AUTOSAR XML (schema 00048)
standard types defined: Boolean, UInt16, UInt32, UInt8, boolean, uint16, uint32, uint8
package /AppNvM_SRPrm_pkg/AppNvM_SRPrm_dt
  impl type rt_Array_UInt8_4: category=ARRAY
    element rt_Array_UInt8_4: array-size=4, array-size-semantics=FIXED-SIZE, implementation-data-type=UInt8
package /AppNvM_SRPrm_pkg/AppNvM_SRPrm_if
  102 x sender receiver interface:
    gCFG_bLCK_PowerFillerCapCfg: invalidation-policy{data-element=gCFG_bLCK_PowerFillerCapCfg/Val, handle-invalid=DONT-INVALIDATE}
      data Val: sw-calibration-access=READ-ONLY, type=AppNvM_SRPrm_dt/Boolean
    gCFG_bReCabinTSnsrAvl: invalidation-policy{data-element=gCFG_bReCabinTSnsrAvl/Val, handle-invalid=DONT-INVALIDATE}
      data Val: type=AppNvM_SRPrm_dt/Boolean
    gCFG_bRLDoorFramelessGlassCfg: invalidation-policy{data-element=gCFG_bRLDoorFramelessGlassCfg/Val, handle-invalid=DONT-INVALIDATE}
      data Val: sw-calibration-access=READ-ONLY, type=AppNvM_SRPrm_dt/Boolean
    gCFG_bRRDoorFramelessGlassCfg: invalidation-policy{data-element=gCFG_bRRDoorFramelessGlassCfg/Val, handle-invalid=DONT-INVALIDATE}
      data Val: sw-calibration-access=READ-ONLY, type=AppNvM_SRPrm_dt/Boolean
    gCFG_bWndVentilationFunCfg: invalidation-policy{data-element=gCFG_bWndVentilationFunCfg/Val, handle-invalid=DONT-INVALIDATE}
      data Val: sw-calibration-access=READ-ONLY, type=AppNvM_SRPrm_dt/Boolean
    gCFG_RearWiperPresent: invalidation-policy{data-element=gCFG_RearWiperPresent/Val, handle-invalid=DONT-INVALIDATE}
      data Val: sw-calibration-access=READ-ONLY, type=AppNvM_SRPrm_dt/Boolean
    gCFG_u8LocalSideWinSwType: invalidation-policy{data-element=gCFG_u8LocalSideWinSwType/Val, handle-invalid=DONT-INVALIDATE}
      data Val: type=UInt8
    gCFG_u8ReBlowrCtrlFreqTyp: invalidation-policy{data-element=gCFG_u8ReBlowrCtrlFreqTyp/Val, handle-invalid=DONT-INVALIDATE}
      data Val: type=UInt8
    gCFG_u8ReBlowrCtrlTyp: invalidation-policy{data-element=gCFG_u8ReBlowrCtrlTyp/Val, handle-invalid=DONT-INVALIDATE}
      data Val: type=UInt8
    gCFG_u8ReHVACBoxTyp: invalidation-policy{data-element=gCFG_u8ReHVACBoxTyp/Val, handle-invalid=DONT-INVALIDATE}
      data Val: type=UInt8
    gCFG_u8SsmInFunctionConfig: invalidation-policy{data-element=gCFG_u8SsmInFunctionConfig/Val, handle-invalid=DONT-INVALIDATE}
      data Val: type=UInt8
    gCFG_u8SsmInVariantCoding: invalidation-policy{data-element=gCFG_u8SsmInVariantCoding/Val, handle-invalid=DONT-INVALIDATE}
      data Val: type=rt_Array_UInt8_4
    gCFG_u8WndAPCfgSet: invalidation-policy{data-element=gCFG_u8WndAPCfgSet/Val, handle-invalid=DONT-INVALIDATE}
      data Val: sw-calibration-access=READ-ONLY, type=UInt8
    gCFG_u8WndVentilationPst: invalidation-policy{data-element=gCFG_u8WndVentilationPst/Val, handle-invalid=DONT-INVALIDATE}
      data Val: sw-calibration-access=READ-ONLY, type=UInt8
    gPRM_bChargeLightEnableCfg: invalidation-policy{data-element=gPRM_bChargeLightEnableCfg/Val, handle-invalid=DONT-INVALIDATE}
      data Val: sw-calibration-access=READ-ONLY, type=AppNvM_SRPrm_dt/Boolean
    gPRM_bCHMSLEnableCfg: invalidation-policy{data-element=gPRM_bCHMSLEnableCfg/Val, handle-invalid=DONT-INVALIDATE}
      data Val: sw-calibration-access=READ-ONLY, type=AppNvM_SRPrm_dt/Boolean
    gPRM_bParkLightEnableCfg: invalidation-policy{data-element=gPRM_bParkLightEnableCfg/Val, handle-invalid=DONT-INVALIDATE}
      data Val: sw-calibration-access=READ-ONLY, type=AppNvM_SRPrm_dt/Boolean
    gPRM_bPODCinchFunEnCfgRL: invalidation-policy{data-element=gPRM_bPODCinchFunEnCfgRL/Val, handle-invalid=DONT-INVALIDATE}
      data Val: sw-calibration-access=READ-ONLY, type=AppNvM_SRPrm_dt/Boolean
    gPRM_bPODCinchFunEnCfgRR: invalidation-policy{data-element=gPRM_bPODCinchFunEnCfgRR/Val, handle-invalid=DONT-INVALIDATE}
      data Val: sw-calibration-access=READ-ONLY, type=AppNvM_SRPrm_dt/Boolean
    gPRM_bPODRelsCinchFunEnCfgRL: invalidation-policy{data-element=gPRM_bPODRelsCinchFunEnCfgRL/Val, handle-invalid=DONT-INVALIDATE}
      data Val: type=DcmAppl_DID_dt/Boolean
    gPRM_bPODRelsCinchFunEnCfgRR: invalidation-policy{data-element=gPRM_bPODRelsCinchFunEnCfgRR/Val, handle-invalid=DONT-INVALIDATE}
      data Val: type=DcmAppl_DID_dt/Boolean
    gPRM_bPositionLightEnableCfg: invalidation-policy{data-element=gPRM_bPositionLightEnableCfg/Val, handle-invalid=DONT-INVALIDATE}
      data Val: sw-calibration-access=READ-ONLY, type=AppNvM_SRPrm_dt/Boolean
    gPRM_bPositionLightTimingOFFEnableCfg: invalidation-policy{data-element=gPRM_bPositionLightTimingOFFEnableCfg/Val, handle-invalid=DONT-INVALIDATE}
      data Val: sw-calibration-access=READ-ONLY, type=AppNvM_SRPrm_dt/Boolean
    gPRM_bRearFogLightEnableCfg: invalidation-policy{data-element=gPRM_bRearFogLightEnableCfg/Val, handle-invalid=DONT-INVALIDATE}
      data Val: sw-calibration-access=READ-ONLY, type=AppNvM_SRPrm_dt/Boolean
    gPRM_bRearTurnLightType: invalidation-policy{data-element=gPRM_bRearTurnLightType/Val, handle-invalid=DONT-INVALIDATE}
      data Val: type=DcmAppl_DID_dt/Boolean
    gPRM_bRearTurnONRearPositionOFFCfg: invalidation-policy{data-element=gPRM_bRearTurnONRearPositionOFFCfg/Val, handle-invalid=DONT-INVALIDATE}
      data Val: sw-calibration-access=READ-ONLY, type=AppNvM_SRPrm_dt/Boolean
    gPRM_bReverseLightEnableCfg: invalidation-policy{data-element=gPRM_bReverseLightEnableCfg/Val, handle-invalid=DONT-INVALIDATE}
      data Val: sw-calibration-access=READ-ONLY, type=AppNvM_SRPrm_dt/Boolean
    gPRM_bSideBrkLightEnableCfg: invalidation-policy{data-element=gPRM_bSideBrkLightEnableCfg/Val, handle-invalid=DONT-INVALIDATE}
      data Val: sw-calibration-access=READ-ONLY, type=AppNvM_SRPrm_dt/Boolean
    gPRM_bTDCSStopEnableCfg: invalidation-policy{data-element=gPRM_bTDCSStopEnableCfg/Val, handle-invalid=DONT-INVALIDATE}
      data Val: sw-calibration-access=READ-ONLY, type=AppNvM_SRPrm_dt/Boolean
    gPRM_bTurnLightEnableCfg: invalidation-policy{data-element=gPRM_bTurnLightEnableCfg/Val, handle-invalid=DONT-INVALIDATE}
      data Val: sw-calibration-access=READ-ONLY, type=AppNvM_SRPrm_dt/Boolean
    gPRM_u16HallHighLevel: invalidation-policy{data-element=gPRM_u16HallHighLevel/Val, handle-invalid=DONT-INVALIDATE}
      data Val: sw-calibration-access=READ-ONLY, type=UInt16
    gPRM_u16HallLowLevel: invalidation-policy{data-element=gPRM_u16HallLowLevel/Val, handle-invalid=DONT-INVALIDATE}
      data Val: sw-calibration-access=READ-ONLY, type=UInt16
    gPRM_u16OverVoltImmPrm: invalidation-policy{data-element=gPRM_u16OverVoltImmPrm/Val, handle-invalid=DONT-INVALIDATE}
      data Val: sw-calibration-access=READ-ONLY, type=UInt16
    gPRM_u16OverVoltPrm: invalidation-policy{data-element=gPRM_u16OverVoltPrm/Val, handle-invalid=DONT-INVALIDATE}
      data Val: sw-calibration-access=READ-ONLY, type=UInt16
    gPRM_u16OverVoltRecoverPrm: invalidation-policy{data-element=gPRM_u16OverVoltRecoverPrm/Val, handle-invalid=DONT-INVALIDATE}
      data Val: sw-calibration-access=READ-ONLY, type=UInt16
    gPRM_u16UnderVoltImmPrm: invalidation-policy{data-element=gPRM_u16UnderVoltImmPrm/Val, handle-invalid=DONT-INVALIDATE}
      data Val: sw-calibration-access=READ-ONLY, type=UInt16
    gPRM_u16UnderVoltPrm: invalidation-policy{data-element=gPRM_u16UnderVoltPrm/Val, handle-invalid=DONT-INVALIDATE}
      data Val: sw-calibration-access=READ-ONLY, type=UInt16
    gPRM_u16UnderVoltRecoverPrm: invalidation-policy{data-element=gPRM_u16UnderVoltRecoverPrm/Val, handle-invalid=DONT-INVALIDATE}
      data Val: sw-calibration-access=READ-ONLY, type=UInt16
    gPRM_u32TempCoolDownPrm: invalidation-policy{data-element=gPRM_u32TempCoolDownPrm/Val, handle-invalid=DONT-INVALIDATE}
      data Val: sw-calibration-access=READ-ONLY, type=UInt32
    gPRM_u32TempDisableAllPrm: invalidation-policy{data-element=gPRM_u32TempDisableAllPrm/Val, handle-invalid=DONT-INVALIDATE}
      data Val: sw-calibration-access=READ-ONLY, type=UInt32
    gPRM_u32TempDisableUpPrm: invalidation-policy{data-element=gPRM_u32TempDisableUpPrm/Val, handle-invalid=DONT-INVALIDATE}
      data Val: sw-calibration-access=READ-ONLY, type=UInt32
    gPRM_u8EnaThermalProtPrm: invalidation-policy{data-element=gPRM_u8EnaThermalProtPrm/Val, handle-invalid=DONT-INVALIDATE}
      data Val: sw-calibration-access=READ-ONLY, type=UInt8
    gPRM_u8FLEnableAutoUpPrm: invalidation-policy{data-element=gPRM_u8FLEnableAutoUpPrm/Val, handle-invalid=DONT-INVALIDATE}
      data Val: sw-calibration-access=READ-ONLY, type=UInt8
    gPRM_u8FREnableAutoUpPrm: invalidation-policy{data-element=gPRM_u8FREnableAutoUpPrm/Val, handle-invalid=DONT-INVALIDATE}
      data Val: sw-calibration-access=READ-ONLY, type=UInt8
    gPRM_u8HallFilterTime: invalidation-policy{data-element=gPRM_u8HallFilterTime/Val, handle-invalid=DONT-INVALIDATE}
      data Val: sw-calibration-access=READ-ONLY, type=UInt8
    gPRM_u8HallOverTime: invalidation-policy{data-element=gPRM_u8HallOverTime/Val, handle-invalid=DONT-INVALIDATE}
      data Val: sw-calibration-access=READ-ONLY, type=UInt8
    gPRM_u8IniHoldTimer: invalidation-policy{data-element=gPRM_u8IniHoldTimer/Val, handle-invalid=DONT-INVALIDATE}
      data Val: sw-calibration-access=READ-ONLY, type=UInt8
    gPRM_u8LicencePlateLightShutDown: invalidation-policy{data-element=gPRM_u8LicencePlateLightShutDown/Val, handle-invalid=DONT-INVALIDATE}
      data Val: sw-calibration-access=READ-ONLY, type=UInt8
    gPRM_u8LocalKeepWakeUpCfg: invalidation-policy{data-element=gPRM_u8LocalKeepWakeUpCfg/Val, handle-invalid=DONT-INVALIDATE}
      data Val: sw-calibration-access=READ-ONLY, type=UInt8
    gPRM_u8MaxRuntimePrm: invalidation-policy{data-element=gPRM_u8MaxRuntimePrm/Val, handle-invalid=DONT-INVALIDATE}
      data Val: sw-calibration-access=READ-ONLY, type=UInt8
    gPRM_u8MinReverseTimePrm: invalidation-policy{data-element=gPRM_u8MinReverseTimePrm/Val, handle-invalid=DONT-INVALIDATE}
      data Val: sw-calibration-access=READ-ONLY, type=UInt8
    gPRM_u8PODCinchActiCntForOverheat: invalidation-policy{data-element=gPRM_u8PODCinchActiCntForOverheat/Val, handle-invalid=DONT-INVALIDATE}
      data Val: sw-calibration-access=READ-ONLY, type=UInt8
    gPRM_u8PODCinchInhibitForOverheat: invalidation-policy{data-element=gPRM_u8PODCinchInhibitForOverheat/Val, handle-invalid=DONT-INVALIDATE}
      data Val: sw-calibration-access=READ-ONLY, type=UInt8
    gPRM_u8PODCinchTWForOverheat: invalidation-policy{data-element=gPRM_u8PODCinchTWForOverheat/Val, handle-invalid=DONT-INVALIDATE}
      data Val: sw-calibration-access=READ-ONLY, type=UInt8
    gPRM_u8PODPowerRelesActiCntForOverheat: invalidation-policy{data-element=gPRM_u8PODPowerRelesActiCntForOverheat/Val, handle-invalid=DONT-INVALIDATE}
      data Val: sw-calibration-access=READ-ONLY, type=UInt8
    gPRM_u8PODPowerRelesInhibitForOverheat: invalidation-policy{data-element=gPRM_u8PODPowerRelesInhibitForOverheat/Val, handle-invalid=DONT-INVALIDATE}
      data Val: sw-calibration-access=READ-ONLY, type=UInt8
    gPRM_u8PODPowerRelesTWForOverheat: invalidation-policy{data-element=gPRM_u8PODPowerRelesTWForOverheat/Val, handle-invalid=DONT-INVALIDATE}
      data Val: sw-calibration-access=READ-ONLY, type=UInt8
    gPRM_u8PODTCinchActv: invalidation-policy{data-element=gPRM_u8PODTCinchActv/Val, handle-invalid=DONT-INVALIDATE}
      data Val: sw-calibration-access=READ-ONLY, type=UInt8
    gPRM_u8PODTmrCinchOper: invalidation-policy{data-element=gPRM_u8PODTmrCinchOper/Val, handle-invalid=DONT-INVALIDATE}
      data Val: sw-calibration-access=READ-ONLY, type=UInt8
    gPRM_u8PODTmrCinchRst: invalidation-policy{data-element=gPRM_u8PODTmrCinchRst/Val, handle-invalid=DONT-INVALIDATE}
      data Val: sw-calibration-access=READ-ONLY, type=UInt8
    gPRM_u8PositionLightShutDown: invalidation-policy{data-element=gPRM_u8PositionLightShutDown/Val, handle-invalid=DONT-INVALIDATE}
      data Val: sw-calibration-access=READ-ONLY, type=UInt8
    gPRM_u8PowerDoorCfg: invalidation-policy{data-element=gPRM_u8PowerDoorCfg/Val, handle-invalid=DONT-INVALIDATE}
      data Val: sw-calibration-access=READ-ONLY, type=UInt8
    gPRM_u8ReAirConditionBoxSpecCfg: invalidation-policy{data-element=gPRM_u8ReAirConditionBoxSpecCfg/Val, handle-invalid=DONT-INVALIDATE}
      data Val: type=UInt8
    gPRM_u8RearWiperAndWashDelayTimeCfg: invalidation-policy{data-element=gPRM_u8RearWiperAndWashDelayTimeCfg/Val, handle-invalid=DONT-INVALIDATE}
      data Val: sw-calibration-access=READ-ONLY, type=UInt8
    gPRM_u8RLEnableAutoUpPrm: invalidation-policy{data-element=gPRM_u8RLEnableAutoUpPrm/Val, handle-invalid=DONT-INVALIDATE}
      data Val: sw-calibration-access=READ-ONLY, type=UInt8
    gPRM_u8RLPowerDoorReqWinOpenPst: invalidation-policy{data-element=gPRM_u8RLPowerDoorReqWinOpenPst/Val, handle-invalid=DONT-INVALIDATE}
      data Val: type=UInt8
    gPRM_u8RLWinShortDropPst: invalidation-policy{data-element=gPRM_u8RLWinShortDropPst/Val, handle-invalid=DONT-INVALIDATE}
      data Val: type=UInt8
    gPRM_u8RREnableAutoUpPrm: invalidation-policy{data-element=gPRM_u8RREnableAutoUpPrm/Val, handle-invalid=DONT-INVALIDATE}
      data Val: sw-calibration-access=READ-ONLY, type=UInt8
    gPRM_u8RRPowerDoorReqWinOpenPst: invalidation-policy{data-element=gPRM_u8RRPowerDoorReqWinOpenPst/Val, handle-invalid=DONT-INVALIDATE}
      data Val: type=UInt8
    gPRM_u8RRWinShortDropPst: invalidation-policy{data-element=gPRM_u8RRWinShortDropPst/Val, handle-invalid=DONT-INVALIDATE}
      data Val: type=UInt8
    gPRM_u8RwpIntervalTime1DelayCfg: invalidation-policy{data-element=gPRM_u8RwpIntervalTime1DelayCfg/Val, handle-invalid=DONT-INVALIDATE}
      data Val: sw-calibration-access=READ-ONLY, type=UInt8
    gPRM_u8RwpIntervalTime2DelayCfg: invalidation-policy{data-element=gPRM_u8RwpIntervalTime2DelayCfg/Val, handle-invalid=DONT-INVALIDATE}
      data Val: sw-calibration-access=READ-ONLY, type=UInt8
    gPRM_u8RwpIntervalTime3DelayCfg: invalidation-policy{data-element=gPRM_u8RwpIntervalTime3DelayCfg/Val, handle-invalid=DONT-INVALIDATE}
      data Val: sw-calibration-access=READ-ONLY, type=UInt8
    gPRM_u8RwpIntervalTime4DelayCfg: invalidation-policy{data-element=gPRM_u8RwpIntervalTime4DelayCfg/Val, handle-invalid=DONT-INVALIDATE}
      data Val: sw-calibration-access=READ-ONLY, type=UInt8
    gPRM_u8RwpIntervalTime5DelayCfg: invalidation-policy{data-element=gPRM_u8RwpIntervalTime5DelayCfg/Val, handle-invalid=DONT-INVALIDATE}
      data Val: sw-calibration-access=READ-ONLY, type=UInt8
    gPRM_u8RwpIntervalTime6DelayCfg: invalidation-policy{data-element=gPRM_u8RwpIntervalTime6DelayCfg/Val, handle-invalid=DONT-INVALIDATE}
      data Val: sw-calibration-access=READ-ONLY, type=UInt8
    gPRM_u8RwpIntervalTime7DelayCfg: invalidation-policy{data-element=gPRM_u8RwpIntervalTime7DelayCfg/Val, handle-invalid=DONT-INVALIDATE}
      data Val: sw-calibration-access=READ-ONLY, type=UInt8
    gPRM_u8RwpParkActivationTimeCfg: invalidation-policy{data-element=gPRM_u8RwpParkActivationTimeCfg/Val, handle-invalid=DONT-INVALIDATE}
      data Val: sw-calibration-access=READ-ONLY, type=UInt8
    gPRM_u8RwpServiceTimeCfg: invalidation-policy{data-element=gPRM_u8RwpServiceTimeCfg/Val, handle-invalid=DONT-INVALIDATE}
      data Val: sw-calibration-access=READ-ONLY, type=UInt8
    gPRM_u8RwpStallTimeCfg: invalidation-policy{data-element=gPRM_u8RwpStallTimeCfg/Val, handle-invalid=DONT-INVALIDATE}
      data Val: sw-calibration-access=READ-ONLY, type=UInt8
    gPRM_u8StaggerTimePrm: invalidation-policy{data-element=gPRM_u8StaggerTimePrm/Val, handle-invalid=DONT-INVALIDATE}
      data Val: sw-calibration-access=READ-ONLY, type=UInt8
    gPRM_u8SwStuckRecoverTimePrm: invalidation-policy{data-element=gPRM_u8SwStuckRecoverTimePrm/Val, handle-invalid=DONT-INVALIDATE}
      data Val: sw-calibration-access=READ-ONLY, type=UInt8
    gPRM_u8SwStuckTimePrm: invalidation-policy{data-element=gPRM_u8SwStuckTimePrm/Val, handle-invalid=DONT-INVALIDATE}
      data Val: sw-calibration-access=READ-ONLY, type=UInt8
    gPRM_u8tAjarKeepAwakeCfg: invalidation-policy{data-element=gPRM_u8tAjarKeepAwakeCfg/Val, handle-invalid=DONT-INVALIDATE}
      data Val: sw-calibration-access=READ-ONLY, type=UInt8
    gPRM_u8tDoorHandleEmergencyCfg: invalidation-policy{data-element=gPRM_u8tDoorHandleEmergencyCfg/Val, handle-invalid=DONT-INVALIDATE}
      data Val: sw-calibration-access=READ-ONLY, type=UInt8
    gPRM_u8tDoorHandleForceCfg: invalidation-policy{data-element=gPRM_u8tDoorHandleForceCfg/Val, handle-invalid=DONT-INVALIDATE}
      data Val: sw-calibration-access=READ-ONLY, type=UInt8
    gPRM_u8tDoorHandleSoftStopCfg: invalidation-policy{data-element=gPRM_u8tDoorHandleSoftStopCfg/Val, handle-invalid=DONT-INVALIDATE}
      data Val: sw-calibration-access=READ-ONLY, type=UInt8
    gPRM_u8tDoorHandleTimeOutCfg: invalidation-policy{data-element=gPRM_u8tDoorHandleTimeOutCfg/Val, handle-invalid=DONT-INVALIDATE}
      data Val: sw-calibration-access=READ-ONLY, type=UInt8
    gPRM_u8tDoorsLockUnlockCfg: invalidation-policy{data-element=gPRM_u8tDoorsLockUnlockCfg/Val, handle-invalid=DONT-INVALIDATE}
      data Val: sw-calibration-access=READ-ONLY, type=UInt8
    gPRM_u8tFillerCapLockUnlockCfg: invalidation-policy{data-element=gPRM_u8tFillerCapLockUnlockCfg/Val, handle-invalid=DONT-INVALIDATE}
      data Val: sw-calibration-access=READ-ONLY, type=UInt8
    gPRM_u8tIntervalEmgcUnlockCfg: invalidation-policy{data-element=gPRM_u8tIntervalEmgcUnlockCfg/Val, handle-invalid=DONT-INVALIDATE}
      data Val: sw-calibration-access=READ-ONLY, type=UInt8
    gPRM_u8tIntervalReverseUnlockCfg: invalidation-policy{data-element=gPRM_u8tIntervalReverseUnlockCfg/Val, handle-invalid=DONT-INVALIDATE}
      data Val: sw-calibration-access=READ-ONLY, type=UInt8
    gPRM_u8tPowerCinchCfg: invalidation-policy{data-element=gPRM_u8tPowerCinchCfg/Val, handle-invalid=DONT-INVALIDATE}
      data Val: sw-calibration-access=READ-ONLY, type=UInt8
    gPRM_u8tPowerReleaseCfg: invalidation-policy{data-element=gPRM_u8tPowerReleaseCfg/Val, handle-invalid=DONT-INVALIDATE}
      data Val: sw-calibration-access=READ-ONLY, type=UInt8
    gPRM_u8tPowerReleaseTimeOutCfg: invalidation-policy{data-element=gPRM_u8tPowerReleaseTimeOutCfg/Val, handle-invalid=DONT-INVALIDATE}
      data Val: sw-calibration-access=READ-ONLY, type=UInt8
    gPRM_u8tTrunkUnlockCfg: invalidation-policy{data-element=gPRM_u8tTrunkUnlockCfg/Val, handle-invalid=DONT-INVALIDATE}
      data Val: sw-calibration-access=READ-ONLY, type=UInt8
    gPRM_u8VehicleTypeCfg: invalidation-policy{data-element=gPRM_u8VehicleTypeCfg/Val, handle-invalid=DONT-INVALIDATE}
      data Val: sw-calibration-access=READ-ONLY, type=UInt8
    gPRM_u8VoltProtDelayPrm: invalidation-policy{data-element=gPRM_u8VoltProtDelayPrm/Val, handle-invalid=DONT-INVALIDATE}
      data Val: sw-calibration-access=READ-ONLY, type=UInt8
    gPRM_u8VoltRecoverDelayPrm: invalidation-policy{data-element=gPRM_u8VoltRecoverDelayPrm/Val, handle-invalid=DONT-INVALIDATE}
      data Val: sw-calibration-access=READ-ONLY, type=UInt8
    gPRM_u8WndAPCfgSet: invalidation-policy{data-element=gPRM_u8WndAPCfgSet/Val, handle-invalid=DONT-INVALIDATE}
      data Val: type=UInt8
    gPRM_u8WndVentilationPst: invalidation-policy{data-element=gPRM_u8WndVentilationPst/Val, handle-invalid=DONT-INVALIDATE}
      data Val: type=UInt8
    gPRM_u8ZcuTypePrm: invalidation-policy{data-element=gPRM_u8ZcuTypePrm/Val, handle-invalid=DONT-INVALIDATE}
      data Val: sw-calibration-access=READ-ONLY, type=UInt8
package /AppNvM_SRPrm_pkg/AppNvM_SRPrm_swc
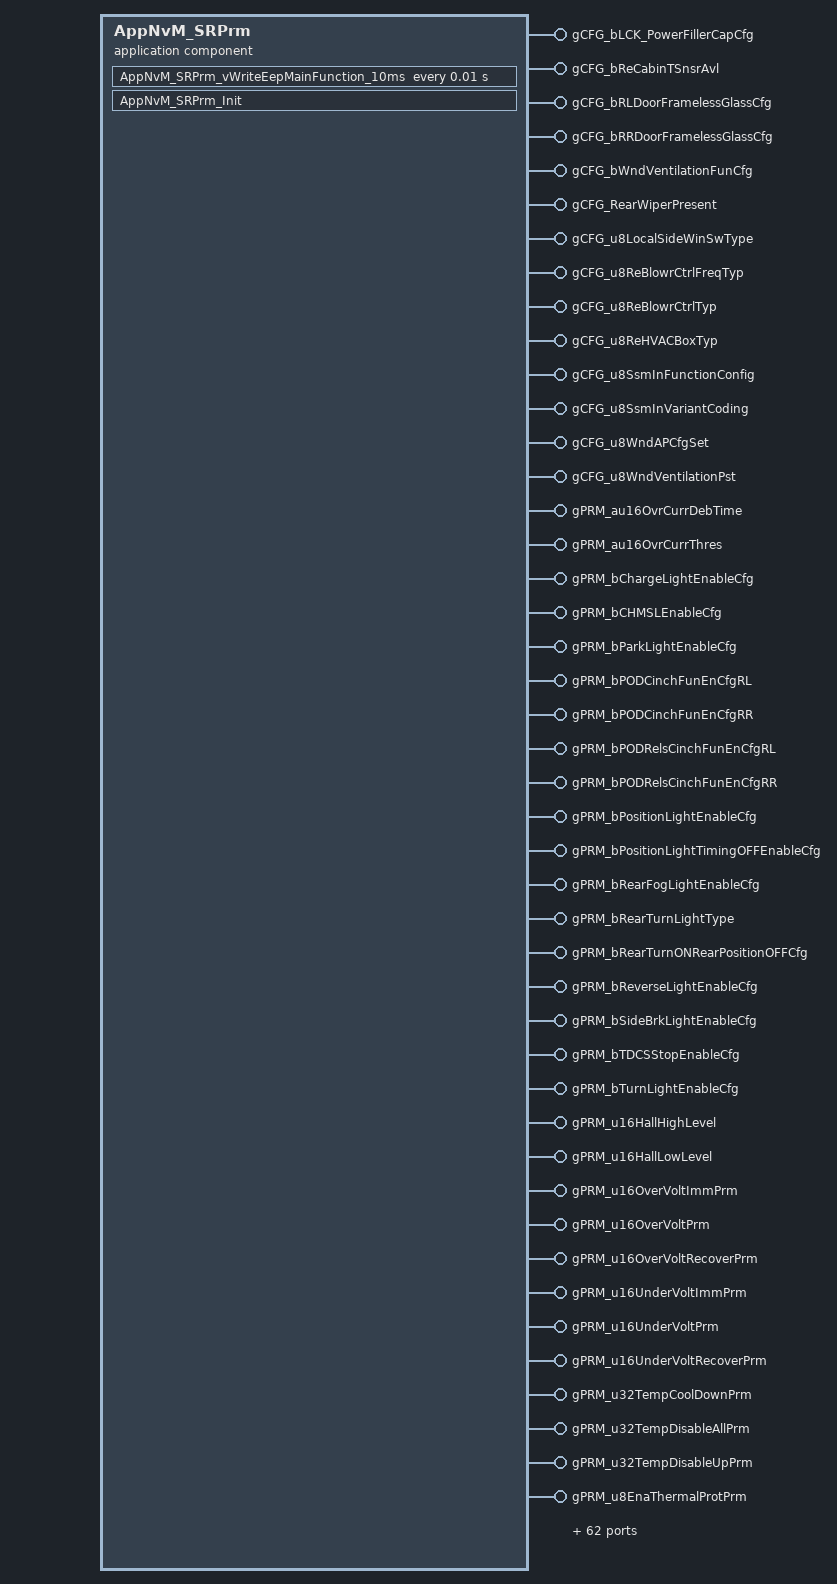
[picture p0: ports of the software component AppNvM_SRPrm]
  application sw component type AppNvM_SRPrm
    106 x provide port:
      gCFG_bLCK_PowerFillerCapCfg: nonqueued-sender-com-spec{data-element=gCFG_bLCK_PowerFillerCapCfg/Val, init-value=0}, provided-interface=gCFG_bLCK_PowerFillerCapCfg
      gCFG_bReCabinTSnsrAvl: nonqueued-sender-com-spec{data-element=gCFG_bReCabinTSnsrAvl/Val, init-value=0}, provided-interface=gCFG_bReCabinTSnsrAvl
      gCFG_bRLDoorFramelessGlassCfg: nonqueued-sender-com-spec{data-element=gCFG_bRLDoorFramelessGlassCfg/Val, init-value=1}, provided-interface=gCFG_bRLDoorFramelessGlassCfg
      gCFG_bRRDoorFramelessGlassCfg: nonqueued-sender-com-spec{data-element=gCFG_bRRDoorFramelessGlassCfg/Val, init-value=1}, provided-interface=gCFG_bRRDoorFramelessGlassCfg
      gCFG_bWndVentilationFunCfg: nonqueued-sender-com-spec{data-element=gCFG_bWndVentilationFunCfg/Val, init-value=1}, provided-interface=gCFG_bWndVentilationFunCfg
      gCFG_RearWiperPresent: nonqueued-sender-com-spec{data-element=gCFG_RearWiperPresent/Val, init-value=1}, provided-interface=gCFG_RearWiperPresent
      gCFG_u8LocalSideWinSwType: nonqueued-sender-com-spec{data-element=gCFG_u8LocalSideWinSwType/Val, init-value=0}, provided-interface=gCFG_u8LocalSideWinSwType
      gCFG_u8ReBlowrCtrlFreqTyp: nonqueued-sender-com-spec{data-element=gCFG_u8ReBlowrCtrlFreqTyp/Val, init-value=0}, provided-interface=gCFG_u8ReBlowrCtrlFreqTyp
      gCFG_u8ReBlowrCtrlTyp: nonqueued-sender-com-spec{data-element=gCFG_u8ReBlowrCtrlTyp/Val, init-value=0}, provided-interface=gCFG_u8ReBlowrCtrlTyp
      gCFG_u8ReHVACBoxTyp: nonqueued-sender-com-spec{data-element=gCFG_u8ReHVACBoxTyp/Val, init-value=0}, provided-interface=gCFG_u8ReHVACBoxTyp
      gCFG_u8SsmInFunctionConfig: nonqueued-sender-com-spec{data-element=gCFG_u8SsmInFunctionConfig/Val, init-value=0}, provided-interface=gCFG_u8SsmInFunctionConfig
      gCFG_u8SsmInVariantCoding: nonqueued-sender-com-spec{data-element=gCFG_u8SsmInVariantCoding/Val, init-value=[0, 0, 0, 0]}, provided-interface=gCFG_u8SsmInVariantCoding
      gCFG_u8WndAPCfgSet: nonqueued-sender-com-spec{data-element=gCFG_u8WndAPCfgSet/Val, init-value=1}, provided-interface=gCFG_u8WndAPCfgSet
      gCFG_u8WndVentilationPst: nonqueued-sender-com-spec{data-element=gCFG_u8WndVentilationPst/Val, init-value=20}, provided-interface=gCFG_u8WndVentilationPst
      gPRM_au16OvrCurrDebTime: nonqueued-sender-com-spec{data-element=gPRM_au16OvrCurrDebTime/Val, init-value=25 x 500}, provided-interface=gPRM_au16OvrCurrDebTime
      gPRM_au16OvrCurrThres: nonqueued-sender-com-spec{data-element=gPRM_au16OvrCurrThres/Val, init-value=[65535, 22000, 65535, 65535, 65535, 65535, 65535, 65535, 65535, 65535, 65535, 65535, 33000, 28000, 28000, 9500, 1700, 1700, 65535, 65535, 65535, 65535, 65535, 65535, 65535]}, provided-interface=gPRM_au16OvrCurrThres
      gPRM_bChargeLightEnableCfg: nonqueued-sender-com-spec{data-element=gPRM_bChargeLightEnableCfg/Val, init-value=1}, provided-interface=gPRM_bChargeLightEnableCfg
      gPRM_bCHMSLEnableCfg: nonqueued-sender-com-spec{data-element=gPRM_bCHMSLEnableCfg/Val, init-value=1}, provided-interface=gPRM_bCHMSLEnableCfg
      gPRM_bParkLightEnableCfg: nonqueued-sender-com-spec{data-element=gPRM_bParkLightEnableCfg/Val, init-value=0}, provided-interface=gPRM_bParkLightEnableCfg
      gPRM_bPODCinchFunEnCfgRL: nonqueued-sender-com-spec{data-element=gPRM_bPODCinchFunEnCfgRL/Val, init-value=1}, provided-interface=gPRM_bPODCinchFunEnCfgRL
      gPRM_bPODCinchFunEnCfgRR: nonqueued-sender-com-spec{data-element=gPRM_bPODCinchFunEnCfgRR/Val, init-value=1}, provided-interface=gPRM_bPODCinchFunEnCfgRR
      gPRM_bPODRelsCinchFunEnCfgRL: nonqueued-sender-com-spec{data-element=gPRM_bPODRelsCinchFunEnCfgRL/Val, init-value=0}, provided-interface=gPRM_bPODRelsCinchFunEnCfgRL
      gPRM_bPODRelsCinchFunEnCfgRR: nonqueued-sender-com-spec{data-element=gPRM_bPODRelsCinchFunEnCfgRR/Val, init-value=0}, provided-interface=gPRM_bPODRelsCinchFunEnCfgRR
      gPRM_bPositionLightEnableCfg: nonqueued-sender-com-spec{data-element=gPRM_bPositionLightEnableCfg/Val, init-value=1}, provided-interface=gPRM_bPositionLightEnableCfg
      gPRM_bPositionLightTimingOFFEnableCfg: nonqueued-sender-com-spec{data-element=gPRM_bPositionLightTimingOFFEnableCfg/Val, init-value=1}, provided-interface=gPRM_bPositionLightTimingOFFEnableCfg
      gPRM_bRearFogLightEnableCfg: nonqueued-sender-com-spec{data-element=gPRM_bRearFogLightEnableCfg/Val, init-value=1}, provided-interface=gPRM_bRearFogLightEnableCfg
      gPRM_bRearTurnLightType: nonqueued-sender-com-spec{data-element=gPRM_bRearTurnLightType/Val, init-value=0}, provided-interface=gPRM_bRearTurnLightType
      gPRM_bRearTurnONRearPositionOFFCfg: nonqueued-sender-com-spec{data-element=gPRM_bRearTurnONRearPositionOFFCfg/Val, init-value=0}, provided-interface=gPRM_bRearTurnONRearPositionOFFCfg
      gPRM_bReverseLightEnableCfg: nonqueued-sender-com-spec{data-element=gPRM_bReverseLightEnableCfg/Val, init-value=1}, provided-interface=gPRM_bReverseLightEnableCfg
      gPRM_bSideBrkLightEnableCfg: nonqueued-sender-com-spec{data-element=gPRM_bSideBrkLightEnableCfg/Val, init-value=1}, provided-interface=gPRM_bSideBrkLightEnableCfg
      gPRM_bTDCSStopEnableCfg: nonqueued-sender-com-spec{data-element=gPRM_bTDCSStopEnableCfg/Val, init-value=0}, provided-interface=gPRM_bTDCSStopEnableCfg
      gPRM_bTurnLightEnableCfg: nonqueued-sender-com-spec{data-element=gPRM_bTurnLightEnableCfg/Val, init-value=1}, provided-interface=gPRM_bTurnLightEnableCfg
      gPRM_u16HallHighLevel: nonqueued-sender-com-spec{data-element=gPRM_u16HallHighLevel/Val, init-value=3050}, provided-interface=gPRM_u16HallHighLevel
      gPRM_u16HallLowLevel: nonqueued-sender-com-spec{data-element=gPRM_u16HallLowLevel/Val, init-value=3051}, provided-interface=gPRM_u16HallLowLevel
      gPRM_u16OverVoltImmPrm: nonqueued-sender-com-spec{data-element=gPRM_u16OverVoltImmPrm/Val, init-value=18000}, provided-interface=gPRM_u16OverVoltImmPrm
      gPRM_u16OverVoltPrm: nonqueued-sender-com-spec{data-element=gPRM_u16OverVoltPrm/Val, init-value=16000}, provided-interface=gPRM_u16OverVoltPrm
      gPRM_u16OverVoltRecoverPrm: nonqueued-sender-com-spec{data-element=gPRM_u16OverVoltRecoverPrm/Val, init-value=15600}, provided-interface=gPRM_u16OverVoltRecoverPrm
      gPRM_u16UnderVoltImmPrm: nonqueued-sender-com-spec{data-element=gPRM_u16UnderVoltImmPrm/Val, init-value=7000}, provided-interface=gPRM_u16UnderVoltImmPrm
      gPRM_u16UnderVoltPrm: nonqueued-sender-com-spec{data-element=gPRM_u16UnderVoltPrm/Val, init-value=10000}, provided-interface=gPRM_u16UnderVoltPrm
      gPRM_u16UnderVoltRecoverPrm: nonqueued-sender-com-spec{data-element=gPRM_u16UnderVoltRecoverPrm/Val, init-value=10600}, provided-interface=gPRM_u16UnderVoltRecoverPrm
      gPRM_u32TempCoolDownPrm: nonqueued-sender-com-spec{data-element=gPRM_u32TempCoolDownPrm/Val, init-value=80}, provided-interface=gPRM_u32TempCoolDownPrm
      gPRM_u32TempDisableAllPrm: nonqueued-sender-com-spec{data-element=gPRM_u32TempDisableAllPrm/Val, init-value=120}, provided-interface=gPRM_u32TempDisableAllPrm
      gPRM_u32TempDisableUpPrm: nonqueued-sender-com-spec{data-element=gPRM_u32TempDisableUpPrm/Val, init-value=100}, provided-interface=gPRM_u32TempDisableUpPrm
      gPRM_u8EnaThermalProtPrm: nonqueued-sender-com-spec{data-element=gPRM_u8EnaThermalProtPrm/Val, init-value=1}, provided-interface=gPRM_u8EnaThermalProtPrm
      gPRM_u8FLEnableAutoUpPrm: nonqueued-sender-com-spec{data-element=gPRM_u8FLEnableAutoUpPrm/Val, init-value=1}, provided-interface=gPRM_u8FLEnableAutoUpPrm
      gPRM_u8FREnableAutoUpPrm: nonqueued-sender-com-spec{data-element=gPRM_u8FREnableAutoUpPrm/Val, init-value=1}, provided-interface=gPRM_u8FREnableAutoUpPrm
      gPRM_u8HallFilterTime: nonqueued-sender-com-spec{data-element=gPRM_u8HallFilterTime/Val, init-value=0}, provided-interface=gPRM_u8HallFilterTime
      gPRM_u8HallOverTime: nonqueued-sender-com-spec{data-element=gPRM_u8HallOverTime/Val, init-value=100}, provided-interface=gPRM_u8HallOverTime
      gPRM_u8IniHoldTimer: nonqueued-sender-com-spec{data-element=gPRM_u8IniHoldTimer/Val, init-value=4}, provided-interface=gPRM_u8IniHoldTimer
      gPRM_u8LicencePlateLightShutDown: nonqueued-sender-com-spec{data-element=gPRM_u8LicencePlateLightShutDown/Val, init-value=93}, provided-interface=gPRM_u8LicencePlateLightShutDown
      gPRM_u8LocalKeepWakeUpCfg: nonqueued-sender-com-spec{data-element=gPRM_u8LocalKeepWakeUpCfg/Val, init-value=5}, provided-interface=gPRM_u8LocalKeepWakeUpCfg
      gPRM_u8MaxRuntimePrm: nonqueued-sender-com-spec{data-element=gPRM_u8MaxRuntimePrm/Val, init-value=120}, provided-interface=gPRM_u8MaxRuntimePrm
      gPRM_u8MinReverseTimePrm: nonqueued-sender-com-spec{data-element=gPRM_u8MinReverseTimePrm/Val, init-value=0}, provided-interface=gPRM_u8MinReverseTimePrm
      gPRM_u8PODCinchActiCntForOverheat: nonqueued-sender-com-spec{data-element=gPRM_u8PODCinchActiCntForOverheat/Val, init-value=10}, provided-interface=gPRM_u8PODCinchActiCntForOverheat
      gPRM_u8PODCinchInhibitForOverheat: nonqueued-sender-com-spec{data-element=gPRM_u8PODCinchInhibitForOverheat/Val, init-value=30}, provided-interface=gPRM_u8PODCinchInhibitForOverheat
      gPRM_u8PODCinchTWForOverheat: nonqueued-sender-com-spec{data-element=gPRM_u8PODCinchTWForOverheat/Val, init-value=60}, provided-interface=gPRM_u8PODCinchTWForOverheat
      gPRM_u8PODPowerRelesActiCntForOverheat: nonqueued-sender-com-spec{data-element=gPRM_u8PODPowerRelesActiCntForOverheat/Val, init-value=10}, provided-interface=gPRM_u8PODPowerRelesActiCntForOverheat
      gPRM_u8PODPowerRelesInhibitForOverheat: nonqueued-sender-com-spec{data-element=gPRM_u8PODPowerRelesInhibitForOverheat/Val, init-value=30}, provided-interface=gPRM_u8PODPowerRelesInhibitForOverheat
      gPRM_u8PODPowerRelesTWForOverheat: nonqueued-sender-com-spec{data-element=gPRM_u8PODPowerRelesTWForOverheat/Val, init-value=60}, provided-interface=gPRM_u8PODPowerRelesTWForOverheat
      gPRM_u8PODTCinchActv: nonqueued-sender-com-spec{data-element=gPRM_u8PODTCinchActv/Val, init-value=20}, provided-interface=gPRM_u8PODTCinchActv
      gPRM_u8PODTmrCinchOper: nonqueued-sender-com-spec{data-element=gPRM_u8PODTmrCinchOper/Val, init-value=30}, provided-interface=gPRM_u8PODTmrCinchOper
      gPRM_u8PODTmrCinchRst: nonqueued-sender-com-spec{data-element=gPRM_u8PODTmrCinchRst/Val, init-value=25}, provided-interface=gPRM_u8PODTmrCinchRst
      gPRM_u8PositionLightShutDown: nonqueued-sender-com-spec{data-element=gPRM_u8PositionLightShutDown/Val, init-value=93}, provided-interface=gPRM_u8PositionLightShutDown
      gPRM_u8PowerDoorCfg: nonqueued-sender-com-spec{data-element=gPRM_u8PowerDoorCfg/Val, init-value=3}, provided-interface=gPRM_u8PowerDoorCfg
      gPRM_u8ReAirConditionBoxSpecCfg: nonqueued-sender-com-spec{data-element=gPRM_u8ReAirConditionBoxSpecCfg/Val, init-value=0}, provided-interface=gPRM_u8ReAirConditionBoxSpecCfg
      gPRM_u8RearPositionLightReuseCfg: nonqueued-sender-com-spec{data-element=gPRM_u8RearPositionLightReuseCfg/Val, init-value=0}, provided-interface=gPRM_u8RearPositionLightReuseCfg
      gPRM_u8RearWiperAndWashDelayTimeCfg: nonqueued-sender-com-spec{data-element=gPRM_u8RearWiperAndWashDelayTimeCfg/Val, init-value=5}, provided-interface=gPRM_u8RearWiperAndWashDelayTimeCfg
      gPRM_u8RLEnableAutoUpPrm: nonqueued-sender-com-spec{data-element=gPRM_u8RLEnableAutoUpPrm/Val, init-value=1}, provided-interface=gPRM_u8RLEnableAutoUpPrm
      gPRM_u8RLPowerDoorReqWinOpenPst: nonqueued-sender-com-spec{data-element=gPRM_u8RLPowerDoorReqWinOpenPst/Val, init-value=0}, provided-interface=gPRM_u8RLPowerDoorReqWinOpenPst
      gPRM_u8RLWinShortDropPst: nonqueued-sender-com-spec{data-element=gPRM_u8RLWinShortDropPst/Val, init-value=0}, provided-interface=gPRM_u8RLWinShortDropPst
      gPRM_u8RREnableAutoUpPrm: nonqueued-sender-com-spec{data-element=gPRM_u8RREnableAutoUpPrm/Val, init-value=1}, provided-interface=gPRM_u8RREnableAutoUpPrm
      gPRM_u8RRPowerDoorReqWinOpenPst: nonqueued-sender-com-spec=data-element=gPRM_u8RRPowerDoorReqWinOpenPst/Val, provided-interface=gPRM_u8RRPowerDoorReqWinOpenPst
      gPRM_u8RRWinShortDropPst: nonqueued-sender-com-spec{data-element=gPRM_u8RRWinShortDropPst/Val, init-value=0}, provided-interface=gPRM_u8RRWinShortDropPst
      gPRM_u8RwpIntervalTime1DelayCfg: nonqueued-sender-com-spec{data-element=gPRM_u8RwpIntervalTime1DelayCfg/Val, init-value=12}, provided-interface=gPRM_u8RwpIntervalTime1DelayCfg
      gPRM_u8RwpIntervalTime2DelayCfg: nonqueued-sender-com-spec{data-element=gPRM_u8RwpIntervalTime2DelayCfg/Val, init-value=10}, provided-interface=gPRM_u8RwpIntervalTime2DelayCfg
      gPRM_u8RwpIntervalTime3DelayCfg: nonqueued-sender-com-spec{data-element=gPRM_u8RwpIntervalTime3DelayCfg/Val, init-value=8}, provided-interface=gPRM_u8RwpIntervalTime3DelayCfg
      gPRM_u8RwpIntervalTime4DelayCfg: nonqueued-sender-com-spec{data-element=gPRM_u8RwpIntervalTime4DelayCfg/Val, init-value=6}, provided-interface=gPRM_u8RwpIntervalTime4DelayCfg
      gPRM_u8RwpIntervalTime5DelayCfg: nonqueued-sender-com-spec{data-element=gPRM_u8RwpIntervalTime5DelayCfg/Val, init-value=4}, provided-interface=gPRM_u8RwpIntervalTime5DelayCfg
      gPRM_u8RwpIntervalTime6DelayCfg: nonqueued-sender-com-spec{data-element=gPRM_u8RwpIntervalTime6DelayCfg/Val, init-value=2}, provided-interface=gPRM_u8RwpIntervalTime6DelayCfg
      gPRM_u8RwpIntervalTime7DelayCfg: nonqueued-sender-com-spec{data-element=gPRM_u8RwpIntervalTime7DelayCfg/Val, init-value=1}, provided-interface=gPRM_u8RwpIntervalTime7DelayCfg
      gPRM_u8RwpParkActivationTimeCfg: nonqueued-sender-com-spec{data-element=gPRM_u8RwpParkActivationTimeCfg/Val, init-value=40}, provided-interface=gPRM_u8RwpParkActivationTimeCfg
      gPRM_u8RwpServiceTimeCfg: nonqueued-sender-com-spec{data-element=gPRM_u8RwpServiceTimeCfg/Val, init-value=40}, provided-interface=gPRM_u8RwpServiceTimeCfg
      gPRM_u8RwpStallTimeCfg: nonqueued-sender-com-spec{data-element=gPRM_u8RwpStallTimeCfg/Val, init-value=10}, provided-interface=gPRM_u8RwpStallTimeCfg
      gPRM_u8StaggerTimePrm: nonqueued-sender-com-spec{data-element=gPRM_u8StaggerTimePrm/Val, init-value=1}, provided-interface=gPRM_u8StaggerTimePrm
      gPRM_u8SwStuckRecoverTimePrm: nonqueued-sender-com-spec{data-element=gPRM_u8SwStuckRecoverTimePrm/Val, init-value=5}, provided-interface=gPRM_u8SwStuckRecoverTimePrm
      gPRM_u8SwStuckTimePrm: nonqueued-sender-com-spec{data-element=gPRM_u8SwStuckTimePrm/Val, init-value=60}, provided-interface=gPRM_u8SwStuckTimePrm
      gPRM_u8tAjarKeepAwakeCfg: nonqueued-sender-com-spec{data-element=gPRM_u8tAjarKeepAwakeCfg/Val, init-value=90}, provided-interface=gPRM_u8tAjarKeepAwakeCfg
      gPRM_u8tDoorHandleEmergencyCfg: nonqueued-sender-com-spec{data-element=gPRM_u8tDoorHandleEmergencyCfg/Val, init-value=50}, provided-interface=gPRM_u8tDoorHandleEmergencyCfg
      gPRM_u8tDoorHandleForceCfg: nonqueued-sender-com-spec{data-element=gPRM_u8tDoorHandleForceCfg/Val, init-value=30}, provided-interface=gPRM_u8tDoorHandleForceCfg
      gPRM_u8tDoorHandleSoftStopCfg: nonqueued-sender-com-spec{data-element=gPRM_u8tDoorHandleSoftStopCfg/Val, init-value=30}, provided-interface=gPRM_u8tDoorHandleSoftStopCfg
      gPRM_u8tDoorHandleTimeOutCfg: nonqueued-sender-com-spec{data-element=gPRM_u8tDoorHandleTimeOutCfg/Val, init-value=20}, provided-interface=gPRM_u8tDoorHandleTimeOutCfg
      gPRM_u8tDoorsLockUnlockCfg: nonqueued-sender-com-spec{data-element=gPRM_u8tDoorsLockUnlockCfg/Val, init-value=20}, provided-interface=gPRM_u8tDoorsLockUnlockCfg
      gPRM_u8tFillerCapLockUnlockCfg: nonqueued-sender-com-spec{data-element=gPRM_u8tFillerCapLockUnlockCfg/Val, init-value=20}, provided-interface=gPRM_u8tFillerCapLockUnlockCfg
      gPRM_u8tIntervalEmgcUnlockCfg: nonqueued-sender-com-spec{data-element=gPRM_u8tIntervalEmgcUnlockCfg/Val, init-value=30}, provided-interface=gPRM_u8tIntervalEmgcUnlockCfg
      gPRM_u8tIntervalReverseUnlockCfg: nonqueued-sender-com-spec{data-element=gPRM_u8tIntervalReverseUnlockCfg/Val, init-value=20}, provided-interface=gPRM_u8tIntervalReverseUnlockCfg
      gPRM_u8tPowerCinchCfg: nonqueued-sender-com-spec{data-element=gPRM_u8tPowerCinchCfg/Val, init-value=30}, provided-interface=gPRM_u8tPowerCinchCfg
      gPRM_u8tPowerReleaseCfg: nonqueued-sender-com-spec{data-element=gPRM_u8tPowerReleaseCfg/Val, init-value=30}, provided-interface=gPRM_u8tPowerReleaseCfg
      gPRM_u8tPowerReleaseTimeOutCfg: nonqueued-sender-com-spec{data-element=gPRM_u8tPowerReleaseTimeOutCfg/Val, init-value=50}, provided-interface=gPRM_u8tPowerReleaseTimeOutCfg
      gPRM_u8tTrunkUnlockCfg: nonqueued-sender-com-spec{data-element=gPRM_u8tTrunkUnlockCfg/Val, init-value=40}, provided-interface=gPRM_u8tTrunkUnlockCfg
      gPRM_u8VehicleTypeCfg: nonqueued-sender-com-spec{data-element=gPRM_u8VehicleTypeCfg/Val, init-value=0}, provided-interface=gPRM_u8VehicleTypeCfg
      gPRM_u8VehRLCM: nonqueued-sender-com-spec{data-element=gPRM_u8VehRLCM/Val, init-value=0}, provided-interface=gPRM_u8VehRLCM
      gPRM_u8VoltProtDelayPrm: nonqueued-sender-com-spec{data-element=gPRM_u8VoltProtDelayPrm/Val, init-value=1}, provided-interface=gPRM_u8VoltProtDelayPrm
      gPRM_u8VoltRecoverDelayPrm: nonqueued-sender-com-spec{data-element=gPRM_u8VoltRecoverDelayPrm/Val, init-value=10}, provided-interface=gPRM_u8VoltRecoverDelayPrm
      gPRM_u8WndAPCfgSet: nonqueued-sender-com-spec{data-element=gPRM_u8WndAPCfgSet/Val, init-value=0}, provided-interface=gPRM_u8WndAPCfgSet
      gPRM_u8WndVentilationPst: nonqueued-sender-com-spec{data-element=gPRM_u8WndVentilationPst/Val, init-value=0}, provided-interface=gPRM_u8WndVentilationPst
      gPRM_u8ZcuTypePrm: nonqueued-sender-com-spec{data-element=gPRM_u8ZcuTypePrm/Val, init-value=0}, provided-interface=gPRM_u8ZcuTypePrm
    behavior AppNvM_SRPrm
      init event AppNvM_SRPrm_InitEvent_1: start-on-event=AppNvM_SRPrm_Init
      timing event TMT_AppNvM_SRPrm_vWriteEepMainFunction_10ms: start-on-event=AppNvM_SRPrm_vWriteEepMainFunction_10ms, period=0.01
      runnable AppNvM_SRPrm_Init
      runnable AppNvM_SRPrm_vWriteEepMainFunction_10ms
        data-send-points:
          106 x access:
            SEND_gCFG_bLCK_PowerFillerCapCfg_Val: accessed-variable=gCFG_bLCK_PowerFillerCapCfg.Val
            SEND_gCFG_bReCabinTSnsrAvl_Val: accessed-variable=gCFG_bReCabinTSnsrAvl.Val
            SEND_gCFG_bRLDoorFramelessGlassCfg_Val: accessed-variable=gCFG_bRLDoorFramelessGlassCfg.Val
            SEND_gCFG_bRRDoorFramelessGlassCfg_Val: accessed-variable=gCFG_bRRDoorFramelessGlassCfg.Val
            SEND_gCFG_bWndVentilationFunCfg_Val: accessed-variable=gCFG_bWndVentilationFunCfg.Val
            SEND_gCFG_RearWiperPresent_Val: accessed-variable=gCFG_RearWiperPresent.Val
            SEND_gCFG_u8LocalSideWinSwType_Val: accessed-variable=gCFG_u8LocalSideWinSwType.Val
            SEND_gCFG_u8ReBlowrCtrlFreqTyp_Val: accessed-variable=gCFG_u8ReBlowrCtrlFreqTyp.Val
            SEND_gCFG_u8ReBlowrCtrlTyp_Val: accessed-variable=gCFG_u8ReBlowrCtrlTyp.Val
            SEND_gCFG_u8ReHVACBoxTyp_Val: accessed-variable=gCFG_u8ReHVACBoxTyp.Val
            SEND_gCFG_u8SsmInFunctionConfig_Val: accessed-variable=gCFG_u8SsmInFunctionConfig.Val
            SEND_gCFG_u8SsmInVariantCoding_Val: accessed-variable=gCFG_u8SsmInVariantCoding.Val
            SEND_gCFG_u8WndAPCfgSet_Val: accessed-variable=gCFG_u8WndAPCfgSet.Val
            SEND_gCFG_u8WndVentilationPst_Val: accessed-variable=gCFG_u8WndVentilationPst.Val
            SEND_gPRM_au16OvrCurrDebTime_Val: accessed-variable=gPRM_au16OvrCurrDebTime.Val
            SEND_gPRM_au16OvrCurrThres_Val: accessed-variable=gPRM_au16OvrCurrThres.Val
            SEND_gPRM_bChargeLightEnableCfg_Val: accessed-variable=gPRM_bChargeLightEnableCfg.Val
            SEND_gPRM_bCHMSLEnableCfg_Val: accessed-variable=gPRM_bCHMSLEnableCfg.Val
            SEND_gPRM_bParkLightEnableCfg_Val: accessed-variable=gPRM_bParkLightEnableCfg.Val
            SEND_gPRM_bPODCinchFunEnCfgRL_Val: accessed-variable=gPRM_bPODCinchFunEnCfgRL.Val
            SEND_gPRM_bPODCinchFunEnCfgRR_Val: accessed-variable=gPRM_bPODCinchFunEnCfgRR.Val
            SEND_gPRM_bPODRelsCinchFunEnCfgRL_Val: accessed-variable=gPRM_bPODRelsCinchFunEnCfgRL.Val
            SEND_gPRM_bPODRelsCinchFunEnCfgRR_Val: accessed-variable=gPRM_bPODRelsCinchFunEnCfgRR.Val
            SEND_gPRM_bPositionLightEnableCfg_Val: accessed-variable=gPRM_bPositionLightEnableCfg.Val
            SEND_gPRM_bPositionLightTimingOFFEnableCfg_Val: accessed-variable=gPRM_bPositionLightTimingOFFEnableCfg.Val
            SEND_gPRM_bRearFogLightEnableCfg_Val: accessed-variable=gPRM_bRearFogLightEnableCfg.Val
            SEND_gPRM_bRearTurnLightType_Val: accessed-variable=gPRM_bRearTurnLightType.Val
            SEND_gPRM_bRearTurnONRearPositionOFFCfg_Val: accessed-variable=gPRM_bRearTurnONRearPositionOFFCfg.Val
            SEND_gPRM_bReverseLightEnableCfg_Val: accessed-variable=gPRM_bReverseLightEnableCfg.Val
            SEND_gPRM_bSideBrkLightEnableCfg_Val: accessed-variable=gPRM_bSideBrkLightEnableCfg.Val
            SEND_gPRM_bTDCSStopEnableCfg_Val: accessed-variable=gPRM_bTDCSStopEnableCfg.Val
            SEND_gPRM_bTurnLightEnableCfg_Val: accessed-variable=gPRM_bTurnLightEnableCfg.Val
            SEND_gPRM_u16HallHighLevel_Val: accessed-variable=gPRM_u16HallHighLevel.Val
            SEND_gPRM_u16HallLowLevel_Val: accessed-variable=gPRM_u16HallLowLevel.Val
            SEND_gPRM_u16OverVoltImmPrm_Val: accessed-variable=gPRM_u16OverVoltImmPrm.Val
            SEND_gPRM_u16OverVoltPrm_Val: accessed-variable=gPRM_u16OverVoltPrm.Val
            SEND_gPRM_u16OverVoltRecoverPrm_Val: accessed-variable=gPRM_u16OverVoltRecoverPrm.Val
            SEND_gPRM_u16UnderVoltImmPrm_Val: accessed-variable=gPRM_u16UnderVoltImmPrm.Val
            SEND_gPRM_u16UnderVoltPrm_Val: accessed-variable=gPRM_u16UnderVoltPrm.Val
            SEND_gPRM_u16UnderVoltRecoverPrm_Val: accessed-variable=gPRM_u16UnderVoltRecoverPrm.Val
            SEND_gPRM_u32TempCoolDownPrm_Val: accessed-variable=gPRM_u32TempCoolDownPrm.Val
            SEND_gPRM_u32TempDisableAllPrm_Val: accessed-variable=gPRM_u32TempDisableAllPrm.Val
            SEND_gPRM_u32TempDisableUpPrm_Val: accessed-variable=gPRM_u32TempDisableUpPrm.Val
            SEND_gPRM_u8EnaThermalProtPrm_Val: accessed-variable=gPRM_u8EnaThermalProtPrm.Val
            SEND_gPRM_u8FLEnableAutoUpPrm_Val: accessed-variable=gPRM_u8FLEnableAutoUpPrm.Val
            SEND_gPRM_u8FREnableAutoUpPrm_Val: accessed-variable=gPRM_u8FREnableAutoUpPrm.Val
            SEND_gPRM_u8HallFilterTime_Val: accessed-variable=gPRM_u8HallFilterTime.Val
            SEND_gPRM_u8HallOverTime_Val: accessed-variable=gPRM_u8HallOverTime.Val
            SEND_gPRM_u8IniHoldTimer_Val: accessed-variable=gPRM_u8IniHoldTimer.Val
            SEND_gPRM_u8LicencePlateLightShutDown_Val: accessed-variable=gPRM_u8LicencePlateLightShutDown.Val
            SEND_gPRM_u8LocalKeepWakeUpCfg_Val: accessed-variable=gPRM_u8LocalKeepWakeUpCfg.Val
            SEND_gPRM_u8MaxRuntimePrm_Val: accessed-variable=gPRM_u8MaxRuntimePrm.Val
            SEND_gPRM_u8MinReverseTimePrm_Val: accessed-variable=gPRM_u8MinReverseTimePrm.Val
            SEND_gPRM_u8PODCinchActiCntForOverheat_Val: accessed-variable=gPRM_u8PODCinchActiCntForOverheat.Val
            SEND_gPRM_u8PODCinchInhibitForOverheat_Val: accessed-variable=gPRM_u8PODCinchInhibitForOverheat.Val
            SEND_gPRM_u8PODCinchTWForOverheat_Val: accessed-variable=gPRM_u8PODCinchTWForOverheat.Val
            SEND_gPRM_u8PODPowerRelesActiCntForOverheat_Val: accessed-variable=gPRM_u8PODPowerRelesActiCntForOverheat.Val
            SEND_gPRM_u8PODPowerRelesInhibitForOverheat_Val: accessed-variable=gPRM_u8PODPowerRelesInhibitForOverheat.Val
            SEND_gPRM_u8PODPowerRelesTWForOverheat_Val: accessed-variable=gPRM_u8PODPowerRelesTWForOverheat.Val
            SEND_gPRM_u8PODTCinchActv_Val: accessed-variable=gPRM_u8PODTCinchActv.Val
            SEND_gPRM_u8PODTmrCinchOper_Val: accessed-variable=gPRM_u8PODTmrCinchOper.Val
            SEND_gPRM_u8PODTmrCinchRst_Val: accessed-variable=gPRM_u8PODTmrCinchRst.Val
            SEND_gPRM_u8PositionLightShutDown_Val: accessed-variable=gPRM_u8PositionLightShutDown.Val
            SEND_gPRM_u8PowerDoorCfg_Val: accessed-variable=gPRM_u8PowerDoorCfg.Val
            SEND_gPRM_u8ReAirConditionBoxSpecCfg_Val: accessed-variable=gPRM_u8ReAirConditionBoxSpecCfg.Val
            SEND_gPRM_u8RearPositionLightReuseCfg_Val: accessed-variable=gPRM_u8RearPositionLightReuseCfg.Val
            SEND_gPRM_u8RearWiperAndWashDelayTimeCfg_Val: accessed-variable=gPRM_u8RearWiperAndWashDelayTimeCfg.Val
            SEND_gPRM_u8RLEnableAutoUpPrm_Val: accessed-variable=gPRM_u8RLEnableAutoUpPrm.Val
            SEND_gPRM_u8RLPowerDoorReqWinOpenPst_Val: accessed-variable=gPRM_u8RLPowerDoorReqWinOpenPst.Val
            SEND_gPRM_u8RLWinShortDropPst_Val: accessed-variable=gPRM_u8RLWinShortDropPst.Val
            SEND_gPRM_u8RREnableAutoUpPrm_Val: accessed-variable=gPRM_u8RREnableAutoUpPrm.Val
            SEND_gPRM_u8RRPowerDoorReqWinOpenPst_Val: accessed-variable=gPRM_u8RRPowerDoorReqWinOpenPst.Val
            SEND_gPRM_u8RRWinShortDropPst_Val: accessed-variable=gPRM_u8RRWinShortDropPst.Val
            SEND_gPRM_u8RwpIntervalTime{1..7}DelayCfg_Val: accessed-variable=gPRM_u8RwpIntervalTime{1..7}DelayCfg.Val
            SEND_gPRM_u8RwpParkActivationTimeCfg_Val: accessed-variable=gPRM_u8RwpParkActivationTimeCfg.Val
            SEND_gPRM_u8RwpServiceTimeCfg_Val: accessed-variable=gPRM_u8RwpServiceTimeCfg.Val
            SEND_gPRM_u8RwpStallTimeCfg_Val: accessed-variable=gPRM_u8RwpStallTimeCfg.Val
            SEND_gPRM_u8StaggerTimePrm_Val: accessed-variable=gPRM_u8StaggerTimePrm.Val
            SEND_gPRM_u8SwStuckRecoverTimePrm_Val: accessed-variable=gPRM_u8SwStuckRecoverTimePrm.Val
            SEND_gPRM_u8SwStuckTimePrm_Val: accessed-variable=gPRM_u8SwStuckTimePrm.Val
            SEND_gPRM_u8tAjarKeepAwakeCfg_Val: accessed-variable=gPRM_u8tAjarKeepAwakeCfg.Val
            SEND_gPRM_u8tDoorHandleEmergencyCfg_Val: accessed-variable=gPRM_u8tDoorHandleEmergencyCfg.Val
            SEND_gPRM_u8tDoorHandleForceCfg_Val: accessed-variable=gPRM_u8tDoorHandleForceCfg.Val
            SEND_gPRM_u8tDoorHandleSoftStopCfg_Val: accessed-variable=gPRM_u8tDoorHandleSoftStopCfg.Val
            SEND_gPRM_u8tDoorHandleTimeOutCfg_Val: accessed-variable=gPRM_u8tDoorHandleTimeOutCfg.Val
            SEND_gPRM_u8tDoorsLockUnlockCfg_Val: accessed-variable=gPRM_u8tDoorsLockUnlockCfg.Val
            SEND_gPRM_u8tFillerCapLockUnlockCfg_Val: accessed-variable=gPRM_u8tFillerCapLockUnlockCfg.Val
            SEND_gPRM_u8tIntervalEmgcUnlockCfg_Val: accessed-variable=gPRM_u8tIntervalEmgcUnlockCfg.Val
            SEND_gPRM_u8tIntervalReverseUnlockCfg_Val: accessed-variable=gPRM_u8tIntervalReverseUnlockCfg.Val
            SEND_gPRM_u8tPowerCinchCfg_Val: accessed-variable=gPRM_u8tPowerCinchCfg.Val
            SEND_gPRM_u8tPowerReleaseCfg_Val: accessed-variable=gPRM_u8tPowerReleaseCfg.Val
            SEND_gPRM_u8tPowerReleaseTimeOutCfg_Val: accessed-variable=gPRM_u8tPowerReleaseTimeOutCfg.Val
            SEND_gPRM_u8tTrunkUnlockCfg_Val: accessed-variable=gPRM_u8tTrunkUnlockCfg.Val
            SEND_gPRM_u8VehicleTypeCfg_Val: accessed-variable=gPRM_u8VehicleTypeCfg.Val
            SEND_gPRM_u8VehRLCM_Val: accessed-variable=gPRM_u8VehRLCM.Val
            SEND_gPRM_u8VoltProtDelayPrm_Val: accessed-variable=gPRM_u8VoltProtDelayPrm.Val
            SEND_gPRM_u8VoltRecoverDelayPrm_Val: accessed-variable=gPRM_u8VoltRecoverDelayPrm.Val
            SEND_gPRM_u8WndAPCfgSet_Val: accessed-variable=gPRM_u8WndAPCfgSet.Val
            SEND_gPRM_u8WndVentilationPst_Val: accessed-variable=gPRM_u8WndVentilationPst.Val
            SEND_gPRM_u8ZcuTypePrm_Val: accessed-variable=gPRM_u8ZcuTypePrm.Val
  swc implementation Implementation_AppNvM_SRPrm: behavior=AppNvM_SRPrm
    code-descriptors:
      code Default: artifact-descriptors=autosar-engineering-object={short-label=Default, category=SWSRC}
package /UAES/ASW/DataConstrs
  range DC_uint8: raw 0..255
package /UAES/ASW/ImplementationDataTypes
  impl type rt_Array_uint16_25: category=ARRAY, sw-calibration-access=READ-ONLY, type-emitter=RTE
    element rt_Array_uint16_25: array-size=25, array-size-semantics=FIXED-SIZE, implementation-data-type=uint16
package /UAES/ASW/PortInterfaces
  4 x sender receiver interface:
    gPRM_au16OvrCurrDebTime: invalidation-policy{data-element=gPRM_au16OvrCurrDebTime/Val, handle-invalid=DONT-INVALIDATE}
      data Val: sw-calibration-access=READ-ONLY, range phys 0..6553.5, raw 0..65535, type=rt_Array_uint16_25
    gPRM_au16OvrCurrThres: invalidation-policy{data-element=gPRM_au16OvrCurrThres/Val, handle-invalid=DONT-INVALIDATE}
      data Val: sw-calibration-access=READ-ONLY, range phys 0..6553.5, raw 0..65535, type=rt_Array_uint16_25
    gPRM_u8RearPositionLightReuseCfg: invalidation-policy{data-element=gPRM_u8RearPositionLightReuseCfg/Val, handle-invalid=DONT-INVALIDATE}
      data Val: sw-calibration-access=READ-ONLY, type=uint8
    gPRM_u8VehRLCM: invalidation-policy{data-element=gPRM_u8VehRLCM/Val, handle-invalid=DONT-INVALIDATE}
      data Val: sw-calibration-access=READ-ONLY, type=uint8
